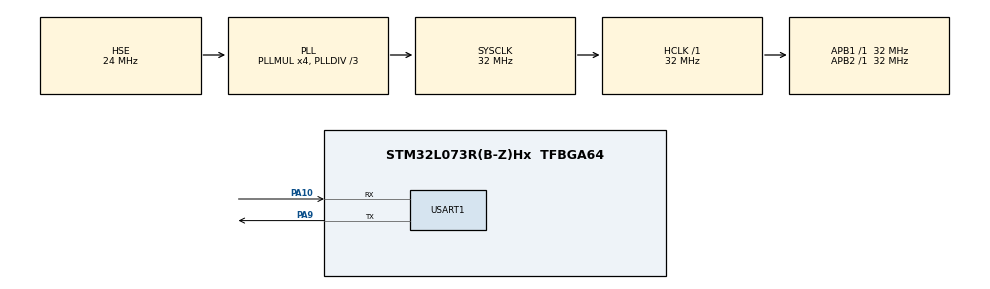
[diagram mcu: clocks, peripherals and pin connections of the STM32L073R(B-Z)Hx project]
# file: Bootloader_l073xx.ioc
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Mcu.Family=STM32L0
Mcu.Name=STM32L073R(B-Z)Hx
Mcu.Package=TFBGA64
PA10.Mode=Asynchronous
PA10.Signal=USART1_RX
PA9.Mode=Asynchronous
PA9.Signal=USART1_TX
PH0-OSC_IN.Mode=HSE-External-Oscillator
PH0-OSC_IN.Signal=RCC_OSC_IN
PH1-OSC_OUT.Mode=HSE-External-Oscillator
PH1-OSC_OUT.Signal=RCC_OSC_OUT
ProjectManager.HeapSize=0x200
ProjectManager.StackSize=0x400
ProjectManager.TargetToolchain=MDK-ARM V5
RCC.AHBFreq_Value=32000000
RCC.APB1Freq_Value=32000000
RCC.APB1TimFreq_Value=32000000
RCC.APB2Freq_Value=32000000
RCC.APB2TimFreq_Value=32000000
RCC.HCLKFreq_Value=32000000
RCC.HSE_VALUE=24000000
RCC.HSI16_VALUE=16000000
RCC.HSI48_VALUE=48000000
RCC.HSI_VALUE=16000000
RCC.LSE_VALUE=32768
RCC.MSI_VALUE=2097000
RCC.PLLDIV=RCC_PLLDIV_3
RCC.PLLMUL=RCC_PLLMUL_4
RCC.PLLSourceVirtual=RCC_PLLSOURCE_HSE
RCC.SYSCLKFreq_VALUE=32000000
RCC.SYSCLKSource=RCC_SYSCLKSOURCE_PLLCLK
RCC.VCOOutputFreq_Value=96000000
USART1.VirtualMode-Asynchronous=VM_ASYNC
VP_CRC_VS_CRC.Mode=CRC_Activate
board=Bootloader_l073xx

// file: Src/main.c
/**
  ******************************************************************************
  * File Name          : main.c
  * Description        : Main program body
  ******************************************************************************
  ** This notice applies to any and all portions of this file
  * that are not between comment pairs USER CODE BEGIN and
  * USER CODE END. Other portions of this file, whether
  * inserted by the user or by software development tools
  * are owned by their respective copyright owners.
  *
  * COPYRIGHT(c) 2017 STMicroelectronics
  *
  * Redistribution and use in source and binary forms, with or without modification,
  * are permitted provided that the following conditions are met:
  *   1. Redistributions of source code must retain the above copyright notice,
  *      this list of conditions and the following disclaimer.
  *   2. Redistributions in binary form must reproduce the above copyright notice,
  *      this list of conditions and the following disclaimer in the documentation
  *      and/or other materials provided with the distribution.
  *   3. Neither the name of STMicroelectronics nor the names of its contributors
  *      may be used to endorse or promote products derived from this software
  *      without specific prior written permission.
  *
  * THIS SOFTWARE IS PROVIDED BY THE COPYRIGHT HOLDERS AND CONTRIBUTORS "AS IS"
  * AND ANY EXPRESS OR IMPLIED WARRANTIES, INCLUDING, BUT NOT LIMITED TO, THE
  * IMPLIED WARRANTIES OF MERCHANTABILITY AND FITNESS FOR A PARTICULAR PURPOSE ARE
  * DISCLAIMED. IN NO EVENT SHALL THE COPYRIGHT HOLDER OR CONTRIBUTORS BE LIABLE
  * FOR ANY DIRECT, INDIRECT, INCIDENTAL, SPECIAL, EXEMPLARY, OR CONSEQUENTIAL
  * DAMAGES (INCLUDING, BUT NOT LIMITED TO, PROCUREMENT OF SUBSTITUTE GOODS OR
  * SERVICES; LOSS OF USE, DATA, OR PROFITS; OR BUSINESS INTERRUPTION) HOWEVER
  * CAUSED AND ON ANY THEORY OF LIABILITY, WHETHER IN CONTRACT, STRICT LIABILITY,
  * OR TORT (INCLUDING NEGLIGENCE OR OTHERWISE) ARISING IN ANY WAY OUT OF THE USE
  * OF THIS SOFTWARE, EVEN IF ADVISED OF THE POSSIBILITY OF SUCH DAMAGE.
  *
  ******************************************************************************
  */

#include "main.h"
#include "stm32l0xx_hal.h"
#include "crc.h"
#include "usart.h"
#include "gpio.h"
#include <stdbool.h>
#include "menu.h"
/* USER CODE BEGIN Includes */
extern pFunction JumpToApplication;
extern uint32_t JumpAddress;
/* USER CODE END Includes */

/* USER CODE BEGIN PV */
/* Private variables ---------------------------------------------------------*/

/* USER CODE END PV */

void SystemClock_Config(void);

/* USER CODE BEGIN PFP */
/* Private function prototypes -----------------------------------------------*/

/* USER CODE END PFP */

int main(void)
{

  /* MCU Configuration----------------------------------------------------------*/

  /* Reset of all peripherals, Initializes the Flash interface and the Systick. */
  HAL_Init();

  /* Configure the system clock */
  SystemClock_Config();

  /* Initialize all configured peripherals */
  MX_GPIO_Init();
  MX_USART1_UART_Init();
  MX_CRC_Init();

   /* Initialize Key Button mounted on STM32L073Z-EVAL board */
  //BSP_PB_Init(BUTTON_TAMPER, BUTTON_MODE_GPIO);
	bool isApp = true;
  /* Test if Key push-button on STM32L073Z-EVAL Board is pressed */
  if (isApp)
  {
  	/* Initialise Flash */
  	FLASH_If_Init();
  	/* Execute the IAP driver in order to reprogram the Flash */
   // IAP_Init();
    /* Display main menu */
    Main_Menu ();
  }
  /* Keep the user application running */
  else
  {
    /* Test if user code is programmed starting from address "APPLICATION_ADDRESS" */
    if (((*(__IO uint32_t*)APPLICATION_ADDRESS) & 0x2FFE0000 ) == 0x20000000)
    {
      /* Jump to user application */
      JumpAddress = *(__IO uint32_t*) (APPLICATION_ADDRESS + 4);
      JumpToApplication = (pFunction) JumpAddress;
      /* Initialize user application's Stack Pointer */
      __set_MSP(*(__IO uint32_t*) APPLICATION_ADDRESS);
      JumpToApplication();
    }
  }

  while (1)
  {}

}

/** System Clock Configuration
*/
void SystemClock_Config(void)
{

  RCC_OscInitTypeDef RCC_OscInitStruct;
  RCC_ClkInitTypeDef RCC_ClkInitStruct;
  RCC_PeriphCLKInitTypeDef PeriphClkInit;

    /**Configure the main internal regulator output voltage
    */
  __HAL_PWR_VOLTAGESCALING_CONFIG(PWR_REGULATOR_VOLTAGE_SCALE1);

    /**Initializes the CPU, AHB and APB busses clocks
    */
  RCC_OscInitStruct.OscillatorType = RCC_OSCILLATORTYPE_HSE;
  RCC_OscInitStruct.HSEState = RCC_HSE_ON;
  RCC_OscInitStruct.PLL.PLLState = RCC_PLL_ON;
  RCC_OscInitStruct.PLL.PLLSource = RCC_PLLSOURCE_HSE;
  RCC_OscInitStruct.PLL.PLLMUL = RCC_PLLMUL_4;
  RCC_OscInitStruct.PLL.PLLDIV = RCC_PLLDIV_3;
  if (HAL_RCC_OscConfig(&RCC_OscInitStruct) != HAL_OK)
  {
    _Error_Handler(__FILE__, __LINE__);
  }

    /**Initializes the CPU, AHB and APB busses clocks
    */
  RCC_ClkInitStruct.ClockType = RCC_CLOCKTYPE_HCLK|RCC_CLOCKTYPE_SYSCLK
                              |RCC_CLOCKTYPE_PCLK1|RCC_CLOCKTYPE_PCLK2;
  RCC_ClkInitStruct.SYSCLKSource = RCC_SYSCLKSOURCE_PLLCLK;
  RCC_ClkInitStruct.AHBCLKDivider = RCC_SYSCLK_DIV1;
  RCC_ClkInitStruct.APB1CLKDivider = RCC_HCLK_DIV1;
  RCC_ClkInitStruct.APB2CLKDivider = RCC_HCLK_DIV1;

  if (HAL_RCC_ClockConfig(&RCC_ClkInitStruct, FLASH_LATENCY_1) != HAL_OK)
  {
    _Error_Handler(__FILE__, __LINE__);
  }

  PeriphClkInit.PeriphClockSelection = RCC_PERIPHCLK_USART1;
  PeriphClkInit.Usart1ClockSelection = RCC_USART1CLKSOURCE_PCLK2;
  if (HAL_RCCEx_PeriphCLKConfig(&PeriphClkInit) != HAL_OK)
  {
    _Error_Handler(__FILE__, __LINE__);
  }

    /**Configure the Systick interrupt time
    */
  HAL_SYSTICK_Config(HAL_RCC_GetHCLKFreq()/1000);

    /**Configure the Systick
    */
  HAL_SYSTICK_CLKSourceConfig(SYSTICK_CLKSOURCE_HCLK);

  /* SysTick_IRQn interrupt configuration */
  HAL_NVIC_SetPriority(SysTick_IRQn, 0, 0);
}

void _Error_Handler(char * file, int line)
{
  while(1)
  {
  }
}

/************************ (C) COPYRIGHT STMicroelectronics *****END OF FILE****/
